# N32H49X register map
Vendor: Nsingtech Ltd.; File version: 1.0
Registers are 32-bit, read-write, reset 0x0 unless marked. A register's access mark holds for its fields unless they carry their own. Offsets are from the block's base; [hi:lo] are bit positions; {n}, {i} and the like mark numbered series; 'fields as' and 'values as' point back to an identical list.

## PWR
Base 0x40000000
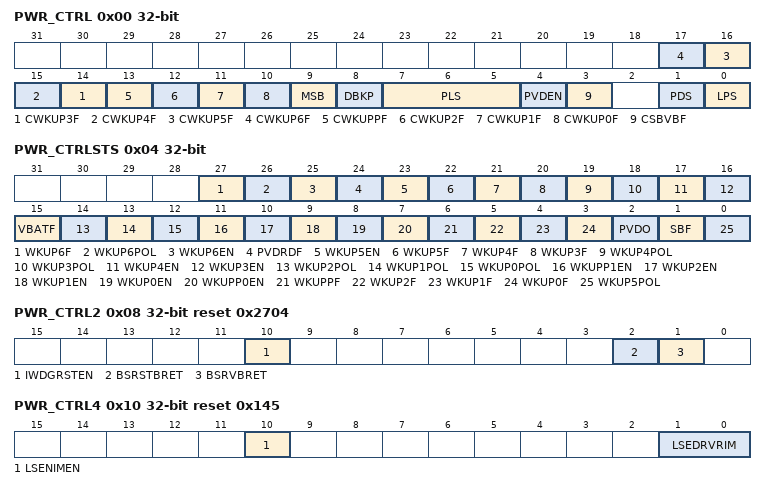
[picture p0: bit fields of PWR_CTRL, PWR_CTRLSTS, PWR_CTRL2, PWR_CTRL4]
0x00 PWR_CTRL
  [n+11] CWKUP{n}F (n=3..6), [13] CWKUPPF, [12] CWKUP2F, [11] CWKUP1F, [10] CWKUP0F, [9] MSB, [8] DBKP, [7:5] PLS, [4] PVDEN, [3] CSBVBF, [1] PDS, [0] LPS
0x04 PWR_CTRLSTS
  [27] WKUP6F ro — WKUP5EN
  [26] WKUP6POL
  [25] WKUP6EN
  [24] PVDRDF ro
  [23] WKUP5EN
  [22] WKUP5F ro
  [21] WKUP4F ro
  [20] WKUP3F ro
  [19] WKUP4POL
  [18] WKUP3POL
  [17] WKUP4EN
  [16] WKUP3EN
  [15] VBATF ro
  [14] WKUP2POL
  [13] WKUP1POL
  [12] WKUP0POL
  [11] WKUPP1EN
  [10] WKUP2EN
  [9] WKUP1EN
  [8] WKUP0EN
  [7] WKUPP0EN
  [6] WKUPPF ro
  [5] WKUP2F ro
  [4] WKUP1F ro
  [3] WKUP0F ro
  [2] PVDO ro
  [1] SBF ro
  [0] WKUP5POL
0x08 PWR_CTRL2 reset 0x2704
  [10] IWDGRSTEN, [2] BSRSTBRET, [1] BSRVBRET
0x0C PWR_CTRL3 reset 0x9DB2F
  [14] BKRSEL
0x10 PWR_CTRL4 reset 0x145
  [10] LSENIMEN, [1:0] LSEDRVRIM
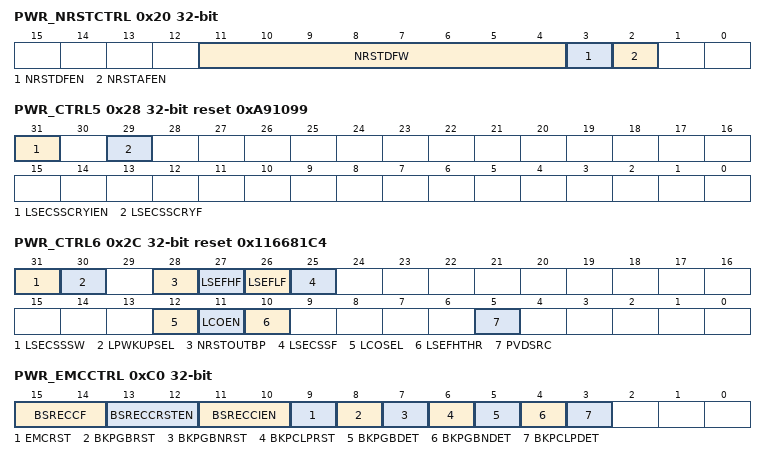
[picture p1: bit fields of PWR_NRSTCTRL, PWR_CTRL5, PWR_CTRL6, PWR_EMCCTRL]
0x20 PWR_NRSTCTRL
  [11:4] NRSTDFW, [3] NRSTDFEN, [2] NRSTAFEN
0x28 PWR_CTRL5 reset 0xA91099
  [31] LSECSSCRYIEN, [29] LSECSSCRYF ro
0x2C PWR_CTRL6 reset 0x116681C4
  [31] LSECSSSW
  [30] LPWKUPSEL
  [28] NRSTOUTBP — NRST analog output bypass
  [27] LSEFHF ro
  [26] LSEFLF ro
  [25] LSECSSF ro
  [12] LCOSEL
  [11] LCOEN
  [10] LSEFHTHR
  [5] PVDSRC
0xC0 PWR_EMCCTRL
  [15:14] BSRECCF, [13:12] BSRECCRSTEN, [11:10] BSRECCIEN, [9] EMCRST, [8] BKPGBRST, [7] BKPGBNRST, [6] BKPCLPRST, [5] BKPGBDET, [4] BKPGBNDET, [3] BKPCLPDET
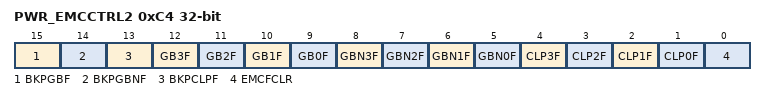
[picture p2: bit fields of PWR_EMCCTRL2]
0xC4 PWR_EMCCTRL2 ro
  [15] BKPGBF, [14] BKPGBNF, [13] BKPCLPF, [n+9] GB{n}F (n=0..3), [n+5] GBN{n}F (n=0..3), [n+1] CLP{n}F (n=0..3), [0] EMCFCLR rw

## RTC — Real time clock
Base 0x40000800
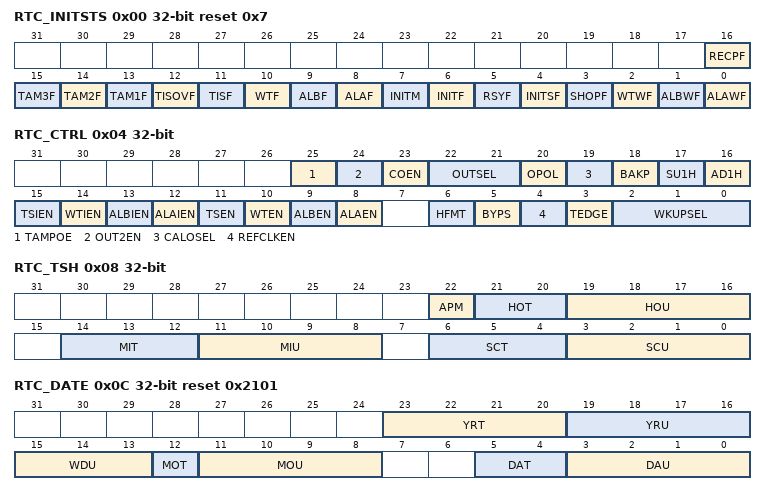
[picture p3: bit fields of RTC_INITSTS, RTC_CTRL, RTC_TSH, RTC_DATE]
0x00 RTC_INITSTS reset 0x7 (reset mask 0x17FFF)
  [16] RECPF, [15] TAM3F, [14] TAM2F, [13] TAM1F, [12] TISOVF, [11] TISF, [10] WTF, [9] ALBF, [8] ALAF, [7] INITM, [6] INITF, [5] RSYF, [4] INITSF, [3] SHOPF, [2] WTWF, [1] ALBWF, [0] ALAWF
0x04 RTC_CTRL (reset mask 0xFFFFFF)
  [25] TAMPOE, [24] OUT2EN, [23] COEN, [22:21] OUTSEL, [20] OPOL, [19] CALOSEL, [18] BAKP, [17] SU1H, [16] AD1H, [15] TSIEN, [14] WTIEN, [13] ALBIEN, [12] ALAIEN, [11] TSEN, [10] WTEN, [9] ALBEN, [8] ALAEN, [6] HFMT, [5] BYPS, [4] REFCLKEN, [3] TEDGE, [2:0] WKUPSEL
0x08 RTC_TSH
  [22] APM, [21:20] HOT, [19:16] HOU, [14:12] MIT, [11:8] MIU, [6:4] SCT, [3:0] SCU
0x0C RTC_DATE reset 0x2101
  [23:20] YRT, [19:16] YRU, [15:13] WDU, [12] MOT, [11:8] MOU, [5:4] DAT, [3:0] DAU
0x10 RTC_WRP
  [7:0] PKEY
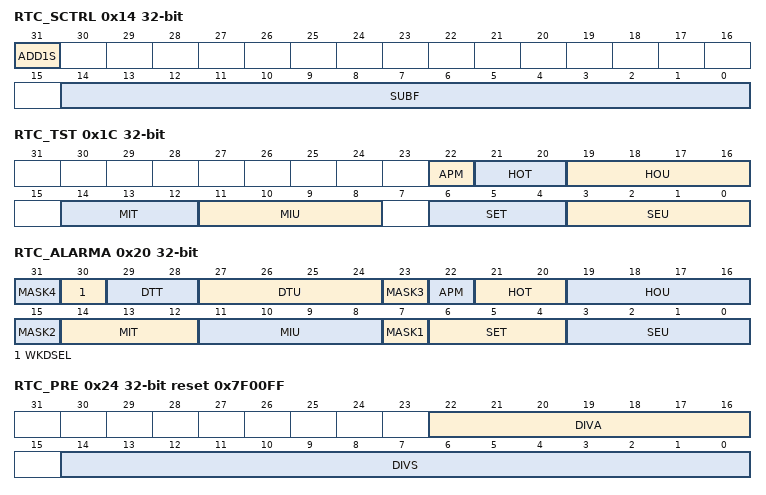
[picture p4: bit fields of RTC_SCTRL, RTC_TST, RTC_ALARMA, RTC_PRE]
0x14 RTC_SCTRL
  [31] ADD1S, [14:0] SUBF
0x18 RTC_SUBS
  [15:0] SS
0x1C RTC_TST (reset mask 0x7F)
  [22] APM, [21:20] HOT, [19:16] HOU, [14:12] MIT, [11:8] MIU, [6:4] SET, [3:0] SEU
0x20 RTC_ALARMA
  [8n-1] MASK{n} (n=1..4), [30] WKDSEL, [29:28] DTT, [27:24] DTU, [22] APM, [21:20] HOT, [19:16] HOU, [14:12] MIT, [11:8] MIU, [6:4] SET, [3:0] SEU
0x24 RTC_PRE reset 0x7F00FF
  [22:16] DIVA, [14:0] DIVS
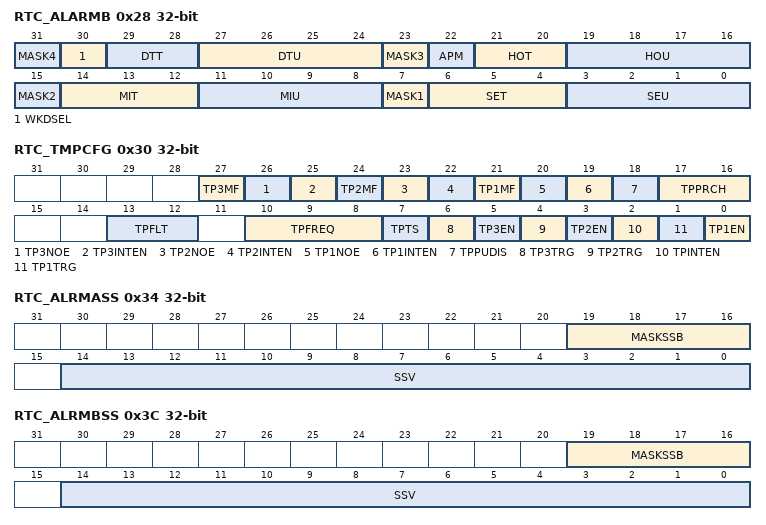
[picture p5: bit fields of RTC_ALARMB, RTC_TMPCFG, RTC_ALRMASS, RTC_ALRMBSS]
0x28 RTC_ALARMB
  fields as RTC_ALARMA
0x2C RTC_WKUPT reset 0xFFFF
  [15:0] WKUPT
0x30 RTC_TMPCFG (reset mask 0x2DFF9F)
  [27] TP3MF, [26] TP3NOE, [25] TP3INTEN, [24] TP2MF, [23] TP2NOE, [22] TP2INTEN, [21] TP1MF, [20] TP1NOE, [19] TP1INTEN, [18] TPPUDIS, [17:16] TPPRCH, [13:12] TPFLT, [10:8] TPFREQ, [7] TPTS, [6] TP3TRG, [5] TP3EN, [4] TP2TRG, [3] TP2EN, [2] TPINTEN, [1] TP1TRG, [0] TP1EN
0x34 RTC_ALRMASS
  [19:16] MASKSSB, [14:0] SSV
0x38 RTC_OPT
  [0] TYPE
0x3C RTC_ALRMBSS
  [19:16] MASKSSB, [14:0] SSV
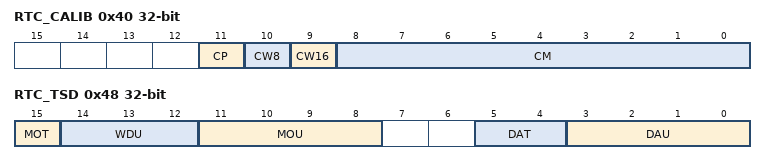
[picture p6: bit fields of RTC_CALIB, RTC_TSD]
0x40 RTC_CALIB (reset mask 0xFF)
  [11] CP, [10] CW8, [9] CW16, [8:0] CM
0x44 RTC_TSSS
  [15:0] SSE
0x48 RTC_TSD
  [15] MOT, [14:12] WDU, [11:8] MOU, [5:4] DAT, [3:0] DAU
{0x48+4i} RTC_BKP{i} (i=1..20)
  [31:0] BF

## EXTI — external interrupt/event controller
Base 0x40010400
0x00 EXTI_EMASK — EXTI event mask register
  [31:0] EMASK — Event mask
0x04 EXTI_IMASK — EXTI interrupt mask register
  [31:0] IMASK — Interrupt mask
0x08 EXTI_FT_CFG — EXTI falling edge trigger configuration register
  [31:0] FT_CFG — Falling edge trigger configuration
0x0C EXTI_RT_CFG — EXTI rising edge trigger configuration register
  [31:0] RT_CFG — Rising edge trigger configuration
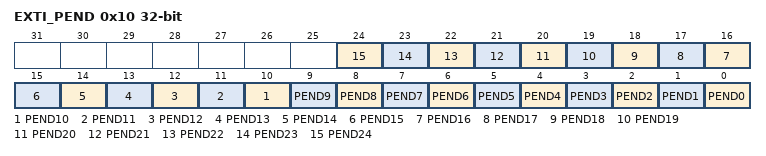
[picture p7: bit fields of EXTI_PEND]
0x10 EXTI_PEND — EXTI pending register
  [n] PEND{n} (n=0..24) — Pending bit on line {n}
0x14 EXTI_SWIE — EXTI software interrupt event register
  [31:0] SWIE — Software interrupt enable
0x18 EXTI_TS_SEL — EXTI timestamp trigger source selection register
  [3:0] TSSEL — Timestamp event source selection
